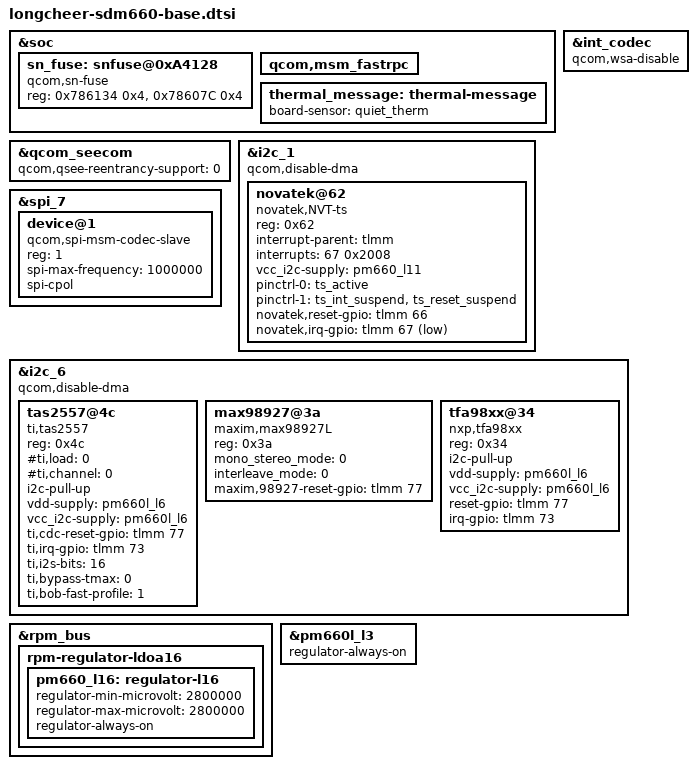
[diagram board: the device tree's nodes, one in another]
// SPDX-License-Identifier: GPL-2.0-only

#include "longcheer-pm660.dtsi"
#include "longcheer-sdm660-camera.dtsi"
#include "longcheer-sdm660-mdss.dtsi"
#include "longcheer-sdm660-mtp.dtsi"
#include "longcheer-sdm660-ramoops.dtsi"

/* sdm660.dtsi common diff */
&soc {
	/delete-node/ qcom,qbt1000;

	sn_fuse: snfuse@0xA4128 {
		compatible = "qcom,sn-fuse";
		reg = <0x786134 0x4>,
			<0x78607C 0x4>;
		reg-names = "sn-base","fuse-state";
	};

	qcom,msm_fastrpc {
		/delete-property/ qcom,fastrpc-adsp-sensors-pdr;
	};

	thermal_message: thermal-message {
		board-sensor = "quiet_therm";
	};
};

&qcom_seecom {
	qcom,qsee-reentrancy-support = <0>;
};

/* sdm660-blsp.dtsi common diff */
&i2c_1 {
	status = "ok";
	qcom,disable-dma;
	novatek@62 {
		compatible = "novatek,NVT-ts";
		reg = <0x62>;
		interrupt-parent = <&tlmm>;
		interrupts = <67 0x2008>;
		vcc_i2c-supply = <&pm660_l11>;
		pinctrl-names = "pmx_ts_active", "pmx_ts_suspend";
		pinctrl-0 = <&ts_active>;
		pinctrl-1 = <&ts_int_suspend &ts_reset_suspend>;
		novatek,reset-gpio = <&tlmm 66 0x00>;
		novatek,irq-gpio = <&tlmm 67 0x2001>;
	};
};

&spi_7 {
	status = "ok";

	device@1 {
		compatible = "qcom,spi-msm-codec-slave";
		#address-cells = <1>;
		#size-cells = <1>;
		reg = <1>; /* Chip select 0 */
		spi-max-frequency = <1000000>;
		spi-cpol;
	};
};

/* sdm660-internal-codec.dtsi common diff */
&int_codec {
	qcom,wsa-disable;
};

&i2c_6 { /* SmartPA TI */
	status = "ok";
	qcom,disable-dma;
	tas2557@4c {
		status = "ok";
		compatible = "ti,tas2557";
		reg = <0x4c>;
		#ti,load = <0>;   /* 0, 8Ohm; 1, 6Ohm; 2, 4Ohm */
		#ti,channel = <0>;   /* 0, left channel; 1, right channel */
		i2c-pull-up;
		vdd-supply = <&pm660l_l6>;
		vcc_i2c-supply = <&pm660l_l6>;
		ti,cdc-reset-gpio = <&tlmm 77 0>;
		ti,irq-gpio = <&tlmm 73 0>;
		ti,i2s-bits = <16>;
		ti,bypass-tmax = <0>;   /* 0, not bypass; 1, bypass */
		ti,bob-fast-profile = <1>; /* 1:voice_handset */
	};

	max98927@3a {
		status = "ok";
		compatible = "maxim,max98927L";
		reg = <0x3a>;
		mono_stereo_mode = <0>;
		interleave_mode = <0>;
		maxim,98927-reset-gpio = <&tlmm 77 0>;
	};

 	tfa98xx@34 {
		status = "ok";
		compatible = "nxp,tfa98xx";
		reg = <0x34>;
		i2c-pull-up;
		vdd-supply = <&pm660l_l6>;
		vcc_i2c-supply = <&pm660l_l6>;
		reset-gpio = <&tlmm 77 0>;
		irq-gpio = <&tlmm 73 0>;
	};
};

/* sdm660-regulator common diff */
&rpm_bus {
	rpm-regulator-ldoa16 {
		status = "ok";
		pm660_l16: regulator-l16 {
			status = "ok";
			regulator-min-microvolt = <2800000>;
			regulator-max-microvolt = <2800000>;
			regulator-always-on;
		};
	};
};

&pm660l_l3 {
	regulator-always-on;
};
